# RCSS_ATL register map
Vendor: Texas Instruments
Peripheral module from a debugger description file (folder am273).
Registers are 32-bit, read-write, no defined reset value unless marked. A register's access mark holds for its fields unless they carry their own. Offsets are as the file gives them; lines under a group give offsets from that group; [hi:lo] are bit positions; {n}, {i} and the like mark numbered series; 'fields as' and 'values as' point back to an identical list; <NAME> marks a mode.

## RCSS_ATL
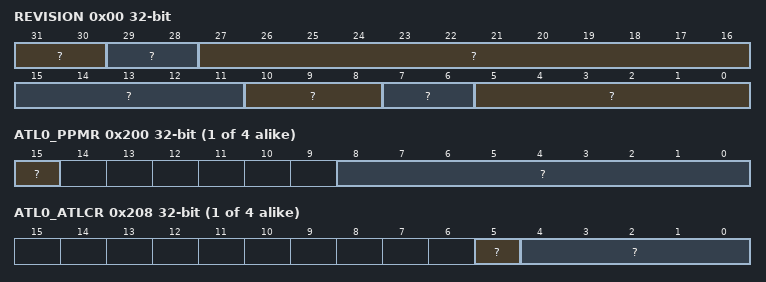
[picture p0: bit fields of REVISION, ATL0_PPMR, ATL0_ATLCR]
0x00 REVISION ro — Peripheral Revision Register
  [31:30] ?, [29:28] ?, [27:16] ?, [15:11] ?, [10:8] ?, [7:6] ?, [5:0] ?
{0x200+0x80*i} ATL{i}_PPMR (i=0..3) — The PPM register is used by the Audio re-timing code. The DAC over-sampling clock will slow down or speed up by the PPM written to bits [8:0].
  [15] ? — 1 = Slow down 0 = Speed up
  [8:0] ? — This is the 9-bit parts-per-millon value in the adjusting circuit. PPM adjustment = PPMSET/2^20
{0x204+0x80*i} ATL{i}_BBSR ro (i=0..3) — The measuring circuit produces a 16-bit Sample Count. Its inputs are the Audio IIS Word Select (AWS) and the Baseband IIS Word Select (BWS) from their respective MCASP pins. The sample count is a read-only register.
  [15:0] ? — This is the 16-bit sample count from the measuring circuit
{0x208+0x80*i} ATL{i}_ATLCR (i=0..3) — The modem Clock Divide Select bit is used during factory calibration of the radio to match latency between the analog and digital signal paths. The ATL Internal Divider divides down the ATL master clock to make ATCLK.
  [5] ? — 0: MODCLK = AWS divided by 2^16 1: MODCLK = AWS divided by 2^12
  [4:0] ? — Sets ratio of ATLPCLK to ATCLK
{0x210+0x80*i} ATL{i}_SWEN (i=0..3) — The software enable register is used to enable/disable the ATL.
  [0] ? — When disabled the ATL registers are forced to known states for simulation purposes. Runtime startup doesn't require initial values because measurement is relative to an arbitrary initial value. All registers are reset to zero except ATLCR.INT_DIV which is resets to 24 (divide-by-25, because zero is not a legal divide ratio.)
{0x214+0x80*i} ATL{i}_BWSMUX (i=0..3) — The Baseband IIS Word Select mux select control register
  [3:0] ? — BWS input select: 0000: atl_io_port_bws[0] 0001: atl_io_port_bws[1] 0010: atl_io_port_bws[2] 0011: atl_io_port_bws[3] 0100: atl_io_port_bws[4] 0101: atl_io_port_bws[5] 0110: atl_io_port_bws[6] 0111: atl_io_port_bws[7] 1000: atl_io_port_bws[8] 1001: atl_io_port_bws[9] 1010: atl_io_port_bws[10] 1011: atl_io_port_bws[11] 1100: atl_io_port_bws[12] 1101: atl_io_port_bws[13] 1110: atl_io_port_bws[14] 1111: atl_io_port_bws[15]
{0x218+0x80*i} ATL{i}_AWSMUX (i=0..3) — The Audio IIS Word Select mux select control register
  [3:0] ? — AWS input select: 0000: atl_io_port_aws[0] 0001: atl_io_port_aws[1] 0010: atl_io_port_aws[2] 0011: atl_io_port_aws[3] 0100: atl_io_port_aws[4] 0101: atl_io_port_aws[5] 0110: atl_io_port_aws[6] 0111: atl_io_port_aws[7] 1000: atl_io_port_aws[8] 1001: atl_io_port_aws[9] 1010: atl_io_port_aws[10] 1011: atl_io_port_aws[11] 1100: atl_io_port_aws[12] 1101: atl_io_port_aws[13] 1110: atl_io_port_aws[14] 1111: atl_io_port_aws[15]
{0x21C+0x80*i} ATL{i}_PCLKMUX (i=0..3) — ATL core input clock mux select control register
  [0] ? — ATL core clock select: 0: vbus_clk 1: atl_clk
